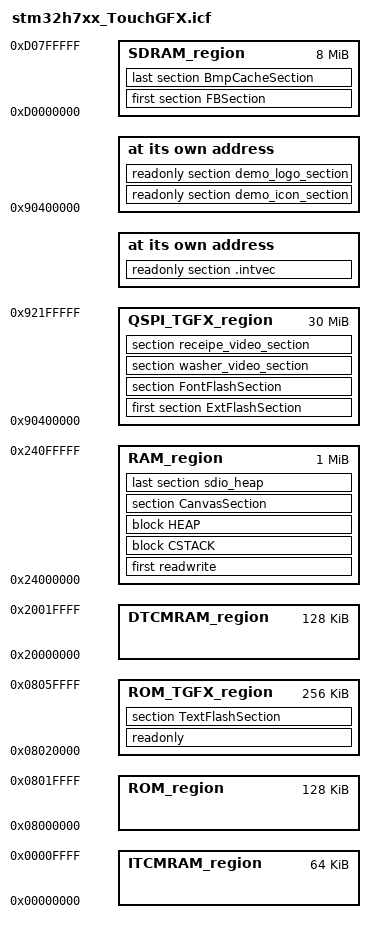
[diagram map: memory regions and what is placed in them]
/*###ICF### Section handled by ICF editor, don't touch! ****/
/*-Editor annotation file-*/
/* IcfEditorFile="$TOOLKIT_DIR$\config\ide\IcfEditor\cortex_v1_0.xml" */
/*-Specials-*/
define symbol __ICFEDIT_intvec_start__ = __C_START_ADDR; /* 0x08020000 */
/*-Memory Regions-*/
define symbol __ICFEDIT_region_ROM_start__        = 0x08000000;
define symbol __ICFEDIT_region_ROM_end__          = 0x0801FFFF; /*  128 Kbytes for the Menu Launcher */

define symbol __ICFEDIT_region_ROM_TGFX_start__   = 0x08020000;
define symbol __ICFEDIT_region_ROM_TGFX_end__     = 0x0805FFFF; /*  256 Kbytes for TouchGFX demo */


/*-Internal RAM Memory Regions-*/
define symbol __ICFEDIT_region_ITCMRAM_start__    = 0x00000000;
define symbol __ICFEDIT_region_ITCMRAM_end__      = 0x0000FFFF; /*   64 Kbytes */
define symbol __ICFEDIT_region_DTCMRAM_start__    = 0x20000000;
define symbol __ICFEDIT_region_DTCMRAM_end__      = 0x2001FFFF; /*  128 Kbytes */
define symbol __ICFEDIT_region_RAM_start__        = 0x24000000;
define symbol __ICFEDIT_region_RAM_end__          = 0x240FFFFF; /* 1024 Kbytes */

/*-External RAM Memory Regions-*/
define symbol __ICFEDIT_region_SDRAM_start__      = 0xD0000000; /*   8 Mbytes */
define symbol __ICFEDIT_region_SDRAM_end__        = 0xD07FFFFF;

/*-Quad-SPI Memory Regions-*/
define symbol __ICFEDIT_region_QSPI_TGFX_start__  = 0x90400000;
define symbol __ICFEDIT_region_QSPI_TGFX_end__    = 0x921FFFFF; /*  30 Mbytes for TouchGFX demo */

/*-Sizes-*/
define symbol __ICFEDIT_size_cstack__ = 0x1000;  /* 4 Kb */
define symbol __ICFEDIT_size_heap__   = 0x1000;  /* 4 Kb */
/**** End of ICF editor section. ###ICF###*/

define memory mem with size = 4G;
define region ROM_region        = mem:[from __ICFEDIT_region_ROM_start__        to __ICFEDIT_region_ROM_end__];
define region ROM_TGFX_region   = mem:[from __ICFEDIT_region_ROM_TGFX_start__   to __ICFEDIT_region_ROM_TGFX_end__];

define region ITCMRAM_region    = mem:[from __ICFEDIT_region_ITCMRAM_start__    to __ICFEDIT_region_ITCMRAM_end__];
define region DTCMRAM_region    = mem:[from __ICFEDIT_region_DTCMRAM_start__    to __ICFEDIT_region_DTCMRAM_end__];
define region RAM_region        = mem:[from __ICFEDIT_region_RAM_start__        to __ICFEDIT_region_RAM_end__];
define region SDRAM_region      = mem:[from __ICFEDIT_region_SDRAM_start__      to __ICFEDIT_region_SDRAM_end__];

define region QSPI_TGFX_region  = mem:[from __ICFEDIT_region_QSPI_TGFX_start__  to __ICFEDIT_region_QSPI_TGFX_end__];

define block CSTACK     with alignment = 8, size = __ICFEDIT_size_cstack__    { };
define block HEAP       with alignment = 8, size = __ICFEDIT_size_heap__      { };

/*-Third Party Demonstration Headers-*/
define symbol __thp_ext_header_start__ = __ICFEDIT_region_QSPI_TGFX_start__;

initialize by copy { readwrite };
do not initialize  { section .noinit, section FBSection, section BmpCacheSection };

place at address mem:__ICFEDIT_intvec_start__ { readonly section .intvec };

/*-Third Party headers Memory Placement-*/
place at address mem:__thp_ext_header_start__   { readonly section demo_icon_section, readonly section demo_logo_section };

place in ITCMRAM_region     { };
place in DTCMRAM_region     { };
place in RAM_region         { first readwrite, block CSTACK, block HEAP, section CanvasSection, last section sdio_heap };
place in SDRAM_region       { first section FBSection, last section BmpCacheSection };

place in ROM_TGFX_region    { readonly, section TextFlashSection };
place in QSPI_TGFX_region   { first section ExtFlashSection
                            , section FontFlashSection
                            , section washer_video_section
                            , section receipe_video_section };
